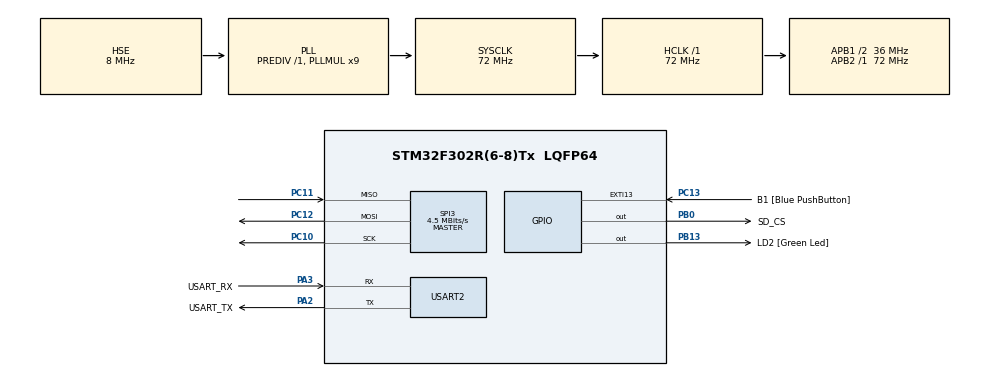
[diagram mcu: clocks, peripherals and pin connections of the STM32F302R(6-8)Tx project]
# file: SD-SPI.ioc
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Mcu.Family=STM32F3
PA2.GPIO_PuPd=GPIO_NOPULL
RCC.CortexFreq_Value=72000000
SPI3.Direction=SPI_DIRECTION_2LINES
SPI3.VirtualType=VM_MASTER
FATFS._USE_LFN=1
PC10.Signal=SPI3_SCK
PC12.Signal=SPI3_MOSI
PA14.GPIO_Label=TCK
RCC.SYSCLKSourceVirtual=RCC_SYSCLKSOURCE_PLLCLK
PA3.GPIO_PuPd=GPIO_NOPULL
PA2.GPIO_Speed=GPIO_SPEED_FREQ_LOW
PB0.GPIO_Label=SD_CS
PC13.GPIO_Label=B1 [Blue PushButton]
PB13.GPIO_Label=LD2 [Green Led]
PA3.GPIO_Speed=GPIO_SPEED_FREQ_LOW
PB13.Signal=GPIO_Output
ProjectManager.StackSize=0x400
RCC.HCLKFreq_Value=72000000
RCC.APB2TimFreq_Value=72000000
RCC.AHBFreq_Value=72000000
PC15\ -\ OSC32_OUT.Signal=RCC_OSC32_OUT
RCC.HSE_VALUE=8000000
USART2.VirtualMode-Asynchronous=VM_ASYNC
RCC.PLLMUL=RCC_PLL_MUL9
PA14.Mode=Serial_Wire
Mcu.Package=LQFP64
SPI3.Mode=SPI_MODE_MASTER
PA2.GPIO_Label=USART_TX
PC11.Mode=Full_Duplex_Master
RCC.APB1TimFreq_Value=72000000
PF1-OSC_OUT.Mode=HSE-External-Oscillator
PF1-OSC_OUT.Signal=RCC_OSC_OUT
PA3.Signal=USART2_RX
PA2.GPIO_Mode=GPIO_MODE_AF_PP
PB3.GPIO_Label=SWO
RCC.PLLSourceVirtual=RCC_PLLSOURCE_HSE
PC11.Signal=SPI3_MISO
PC13.Signal=GPXTI13
PC10.Mode=Full_Duplex_Master
RCC.APB1CLKDivider=RCC_HCLK_DIV2
PA13.Signal=SYS_JTMS-SWDIO
PA3.Mode=Asynchronous
ProjectManager.TargetToolchain=STM32CubeIDE
PA3.GPIO_Mode=GPIO_MODE_AF_PP
RCC.USBFreq_Value=72000000
RCC.LSE_VALUE=32768
PF0-OSC_IN.Mode=HSE-External-Oscillator
VP_FATFS_VS_Generic.Mode=User_defined
PC12.Mode=Full_Duplex_Master
board=NUCLEO-F302R8
RCC.APB2Freq_Value=72000000
SPI3.CalculateBaudRate=4.5 MBits/s
SPI3.BaudRatePrescaler=SPI_BAUDRATEPRESCALER_8
PA13.Mode=Serial_Wire
Mcu.Name=STM32F302R(6-8)Tx
PA13.GPIO_Label=TMS
PA2.Signal=USART2_TX
FATFS._MAX_SS=4096
PB3.Signal=SYS_JTDO-TRACESWO
RCC.SYSCLKFreq_VALUE=72000000
PC13.GPIO_ModeDefaultEXTI=GPIO_MODE_IT_FALLING
PA14.Signal=SYS_JTCK-SWCLK
ProjectManager.HeapSize=0x200
RCC.HSI_VALUE=8000000
RCC.PLLP=RCC_PLLP_DIV4
RCC.PLLQ=7
NVIC.PriorityGroup=NVIC_PRIORITYGROUP_0
RCC.PLLM=8
RCC.PLLN=336
PA2.Mode=Asynchronous
PF0-OSC_IN.Signal=RCC_OSC_IN
RCC.APB1Freq_Value=36000000
PB0.Signal=GPIO_Output
PA3.GPIO_Label=USART_RX
PC14\ -\ OSC32_IN.Signal=RCC_OSC32_IN

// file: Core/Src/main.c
/* USER CODE BEGIN Header */
/**
  ******************************************************************************
  * @file           : main.c
  * @brief          : Main program body
  ******************************************************************************
  * @attention
  *
  * <h2><center>&copy; Copyright (c) 2020 STMicroelectronics.
  * All rights reserved.</center></h2>
  *
  * This software component is licensed by ST under Ultimate Liberty license
  * SLA0044, the "License"; You may not use this file except in compliance with
  * the License. You may obtain a copy of the License at:
  *                             www.st.com/SLA0044
  *
  ******************************************************************************
  */
/* USER CODE END Header */
#include "main.h"
#include "fatfs.h"

/* USER CODE BEGIN Includes */
#include "fatfs_sd.h"
#include <string.h>
#include <stdio.h>
#include <stdbool.h>
/* USER CODE END Includes */

SPI_HandleTypeDef hspi3;

UART_HandleTypeDef huart2;

void SystemClock_Config(void);
static void MX_GPIO_Init(void);
static void MX_SPI3_Init(void);
static void MX_USART2_UART_Init(void);

/* USER CODE BEGIN 0 */

FATFS fs; // file system
FIL fil; // file
FRESULT fresult; // storing result
UINT br, bw; // file read/write count

char msg[140];

FATFS *pfs;
DWORD fre_clust;
uint32_t total, free_space;

/* USER CODE END 0 */

int main(void)
{

  /* MCU Configuration--------------------------------------------------------*/

  /* Reset of all peripherals, Initializes the Flash interface and the Systick. */
  HAL_Init();

  /* Configure the system clock */
  SystemClock_Config();

  /* Initialize all configured peripherals */
  MX_GPIO_Init();
  MX_SPI3_Init();
  MX_FATFS_Init();
  MX_USART2_UART_Init();

//  Wait for SD module reset
  	HAL_Delay(500);

//  Mount SD Card
  	fresult = f_mount(&fs,"",0);
	if(fresult != FR_OK)
	{
	 snprintf(msg, sizeof(msg) - 1, "Mount unsuccessful!\r\n");
	 HAL_UART_Transmit(&huart2, (uint8_t*) msg, strlen(msg), HAL_MAX_DELAY);
	}
	else
	{
	 snprintf(msg, sizeof(msg) - 1, "Mount success!\r\n");
	 HAL_UART_Transmit(&huart2, (uint8_t*) msg, strlen(msg), HAL_MAX_DELAY);
	}

//  Open file to write/ create a file if it doesn`t exist
	 fresult = f_open(&fil, "file1.txt", FA_OPEN_ALWAYS | FA_READ | FA_WRITE);

//  Writing text
	 fresult = f_puts("Hello there", &fil);

//	Close file
	 fresult = f_close(&fil);

//	Open file to read
	 fresult = f_open(&fil, "file.txt", FA_READ);

// Read from file
	 f_gets(msg, sizeof(msg) - 1, &fil);
	 HAL_UART_Transmit(&huart2, (uint8_t*) msg, strlen(msg), HAL_MAX_DELAY);

//	Close file
	 fresult = f_close(&fil);

  /* Infinite loop */
  while (1)
  {

  }
}

void SystemClock_Config(void)
{
  RCC_OscInitTypeDef RCC_OscInitStruct = {0};
  RCC_ClkInitTypeDef RCC_ClkInitStruct = {0};

  /** Initializes the RCC Oscillators according to the specified parameters
  * in the RCC_OscInitTypeDef structure.
  */
  RCC_OscInitStruct.OscillatorType = RCC_OSCILLATORTYPE_HSE;
  RCC_OscInitStruct.HSEState = RCC_HSE_ON;
  RCC_OscInitStruct.HSEPredivValue = RCC_HSE_PREDIV_DIV1;
  RCC_OscInitStruct.HSIState = RCC_HSI_ON;
  RCC_OscInitStruct.PLL.PLLState = RCC_PLL_ON;
  RCC_OscInitStruct.PLL.PLLSource = RCC_PLLSOURCE_HSE;
  RCC_OscInitStruct.PLL.PLLMUL = RCC_PLL_MUL9;
  if (HAL_RCC_OscConfig(&RCC_OscInitStruct) != HAL_OK)
  {
    Error_Handler();
  }
  /** Initializes the CPU, AHB and APB buses clocks
  */
  RCC_ClkInitStruct.ClockType = RCC_CLOCKTYPE_HCLK|RCC_CLOCKTYPE_SYSCLK
                              |RCC_CLOCKTYPE_PCLK1|RCC_CLOCKTYPE_PCLK2;
  RCC_ClkInitStruct.SYSCLKSource = RCC_SYSCLKSOURCE_PLLCLK;
  RCC_ClkInitStruct.AHBCLKDivider = RCC_SYSCLK_DIV1;
  RCC_ClkInitStruct.APB1CLKDivider = RCC_HCLK_DIV2;
  RCC_ClkInitStruct.APB2CLKDivider = RCC_HCLK_DIV1;

  if (HAL_RCC_ClockConfig(&RCC_ClkInitStruct, FLASH_LATENCY_2) != HAL_OK)
  {
    Error_Handler();
  }
}

static void MX_SPI3_Init(void)
{

  /* SPI3 parameter configuration*/
  hspi3.Instance = SPI3;
  hspi3.Init.Mode = SPI_MODE_MASTER;
  hspi3.Init.Direction = SPI_DIRECTION_2LINES;
  hspi3.Init.DataSize = SPI_DATASIZE_4BIT;
  hspi3.Init.CLKPolarity = SPI_POLARITY_LOW;
  hspi3.Init.CLKPhase = SPI_PHASE_1EDGE;
  hspi3.Init.NSS = SPI_NSS_SOFT;
  hspi3.Init.BaudRatePrescaler = SPI_BAUDRATEPRESCALER_8;
  hspi3.Init.FirstBit = SPI_FIRSTBIT_MSB;
  hspi3.Init.TIMode = SPI_TIMODE_DISABLE;
  hspi3.Init.CRCCalculation = SPI_CRCCALCULATION_DISABLE;
  hspi3.Init.CRCPolynomial = 7;
  hspi3.Init.CRCLength = SPI_CRC_LENGTH_DATASIZE;
  hspi3.Init.NSSPMode = SPI_NSS_PULSE_ENABLE;
  if (HAL_SPI_Init(&hspi3) != HAL_OK)
  {
    Error_Handler();
  }

}

static void MX_USART2_UART_Init(void)
{

  huart2.Instance = USART2;
  huart2.Init.BaudRate = 38400;
  huart2.Init.WordLength = UART_WORDLENGTH_8B;
  huart2.Init.StopBits = UART_STOPBITS_1;
  huart2.Init.Parity = UART_PARITY_NONE;
  huart2.Init.Mode = UART_MODE_TX_RX;
  huart2.Init.HwFlowCtl = UART_HWCONTROL_NONE;
  huart2.Init.OverSampling = UART_OVERSAMPLING_16;
  huart2.Init.OneBitSampling = UART_ONE_BIT_SAMPLE_DISABLE;
  huart2.AdvancedInit.AdvFeatureInit = UART_ADVFEATURE_NO_INIT;
  if (HAL_UART_Init(&huart2) != HAL_OK)
  {
    Error_Handler();
  }

}

static void MX_GPIO_Init(void)
{
  GPIO_InitTypeDef GPIO_InitStruct = {0};

  /* GPIO Ports Clock Enable */
  __HAL_RCC_GPIOC_CLK_ENABLE();
  __HAL_RCC_GPIOF_CLK_ENABLE();
  __HAL_RCC_GPIOA_CLK_ENABLE();
  __HAL_RCC_GPIOB_CLK_ENABLE();

  /*Configure GPIO pin Output Level */
  HAL_GPIO_WritePin(GPIOB, SD_CS_Pin|LD2_Pin, GPIO_PIN_RESET);

  /*Configure GPIO pin : B1_Pin */
  GPIO_InitStruct.Pin = B1_Pin;
  GPIO_InitStruct.Mode = GPIO_MODE_IT_FALLING;
  GPIO_InitStruct.Pull = GPIO_NOPULL;
  HAL_GPIO_Init(B1_GPIO_Port, &GPIO_InitStruct);

  /*Configure GPIO pins : SD_CS_Pin LD2_Pin */
  GPIO_InitStruct.Pin = SD_CS_Pin|LD2_Pin;
  GPIO_InitStruct.Mode = GPIO_MODE_OUTPUT_PP;
  GPIO_InitStruct.Pull = GPIO_NOPULL;
  GPIO_InitStruct.Speed = GPIO_SPEED_FREQ_LOW;
  HAL_GPIO_Init(GPIOB, &GPIO_InitStruct);

}

void Error_Handler(void)
{
}

/************************ (C) COPYRIGHT STMicroelectronics *****END OF FILE****/
